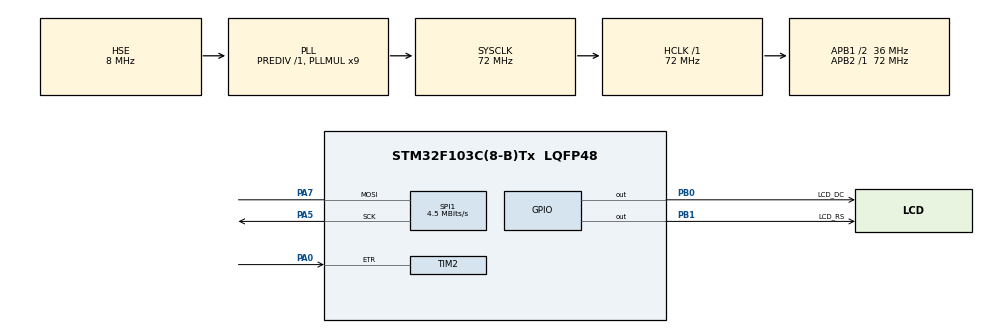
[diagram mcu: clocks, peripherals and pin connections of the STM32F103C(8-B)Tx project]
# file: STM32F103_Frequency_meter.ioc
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Mcu.Family=STM32F1
Mcu.Name=STM32F103C(8-B)Tx
Mcu.Package=LQFP48
NVIC.PriorityGroup=NVIC_PRIORITYGROUP_4
NVIC.TIM1_UP_IRQn=true\:0\:0\:false\:false\:true\:true\:true\:true
PA0-WKUP.Signal=S_TIM2_CH1_ETR
PA13.Mode=Serial_Wire
PA13.Signal=SYS_JTMS-SWDIO
PA14.Mode=Serial_Wire
PA14.Signal=SYS_JTCK-SWCLK
PA5.Mode=Simplex_Bidirectional_Master
PA5.Signal=SPI1_SCK
PA7.Mode=Simplex_Bidirectional_Master
PA7.Signal=SPI1_MOSI
PB0.GPIO_Label=LCD_DC
PB0.GPIO_Speed=GPIO_SPEED_FREQ_HIGH
PB0.Signal=GPIO_Output
PB1.GPIO_Label=LCD_RS
PB1.GPIO_Speed=GPIO_SPEED_FREQ_HIGH
PB1.Signal=GPIO_Output
PD0-OSC_IN.Mode=HSE-External-Oscillator
PD0-OSC_IN.Signal=RCC_OSC_IN
PD1-OSC_OUT.Mode=HSE-External-Oscillator
PD1-OSC_OUT.Signal=RCC_OSC_OUT
ProjectManager.HeapSize=0x200
ProjectManager.StackSize=0x400
ProjectManager.TargetToolchain=STM32CubeIDE
RCC.AHBFreq_Value=72000000
RCC.APB1CLKDivider=RCC_HCLK_DIV2
RCC.APB1Freq_Value=36000000
RCC.APB1TimFreq_Value=72000000
RCC.APB2Freq_Value=72000000
RCC.APB2TimFreq_Value=72000000
RCC.HCLKFreq_Value=72000000
RCC.PLLMUL=RCC_PLL_MUL9
RCC.PLLSourceVirtual=RCC_PLLSOURCE_HSE
RCC.RCC_MCOSource=RCC_MCO1SOURCE_HSE
RCC.SYSCLKFreq_VALUE=72000000
RCC.SYSCLKSource=RCC_SYSCLKSOURCE_PLLCLK
RCC.USBFreq_Value=72000000
SH.S_TIM2_CH1_ETR.0=TIM2_ETR,ClockSourceETR_Mode2
SPI1.BaudRatePrescaler=SPI_BAUDRATEPRESCALER_16
SPI1.CLKPolarity=SPI_POLARITY_HIGH
SPI1.CalculateBaudRate=4.5 MBits/s
SPI1.Direction=SPI_DIRECTION_1LINE
SPI1.Mode=SPI_MODE_MASTER
SPI1.VirtualType=VM_MASTER
TIM1.CounterMode=TIM_COUNTERMODE_DOWN
TIM1.Period=9999
TIM1.Prescaler=7199
TIM1.TIM_MasterOutputTrigger=TIM_TRGO_ENABLE
TIM2.TIM_MasterOutputTrigger=TIM_TRGO_UPDATE
VP_TIM1_VS_ClockSourceINT.Mode=Internal
VP_TIM1_VS_OPM.Mode=OPM_bit
VP_TIM2_VS_ClockSourceITR.Mode=TriggerSource_ITR0
VP_TIM2_VS_ControllerModeGated.Mode=Gated Mode
VP_TIM3_VS_ClockSourceITR.Mode=TriggerSource_ITR1
VP_TIM3_VS_ControllerModeClock.Mode=Clock Mode
board=custom

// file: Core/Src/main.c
/* USER CODE BEGIN Header */
/**
 ******************************************************************************
 * @file           : main.c
 * @brief          : Main program body
 ******************************************************************************
 * @attention
 *
 * Copyright (c) 2022 STMicroelectronics.
 * All rights reserved.
 *
 * This software is licensed under terms that can be found in the LICENSE file
 * in the root directory of this software component.
 * If no LICENSE file comes with this software, it is provided AS-IS.
 *
 ******************************************************************************
 */
/* USER CODE END Header */
#include "main.h"
#include "spi.h"
#include "tim.h"
#include "gpio.h"

/* USER CODE BEGIN Includes */
#include "lcd.h"
/* USER CODE END Includes */

/* USER CODE BEGIN PV */
volatile uint32_t freq = 0;
/* USER CODE END PV */

void SystemClock_Config(void);
/* USER CODE BEGIN PFP */
void HAL_TIM_PeriodElapsedCallback(TIM_HandleTypeDef *htim) {
	if (htim == &htim1) {
		freq = TIM2->CNT + (TIM3->CNT << 16);
		HAL_TIM_Base_Stop_IT(&htim1);
		__HAL_TIM_SET_COUNTER(&htim2, 0x0000);
		__HAL_TIM_SET_COUNTER(&htim3, 0x0000);
		HAL_TIM_Base_Start_IT(&htim1);
	}
}
/* USER CODE END PFP */

int main(void) {

	/* MCU Configuration--------------------------------------------------------*/

	/* Reset of all peripherals, Initializes the Flash interface and the Systick. */
	HAL_Init();

	/* Configure the system clock */
	SystemClock_Config();

	/* Initialize all configured peripherals */
	MX_GPIO_Init();
	MX_TIM1_Init();
	MX_TIM2_Init();
	MX_TIM3_Init();
	MX_SPI1_Init();
	/* USER CODE BEGIN 2 */
	HAL_Delay(100);
	HAL_TIM_Base_Start_IT(&htim1);
	HAL_TIM_Base_Start(&htim2);
	HAL_TIM_Base_Start(&htim3);

	/* USER CODE END 2 */

	/* Infinite loop */
	/* USER CODE BEGIN WHILE */

	LCD_Init(&hspi1);

	while (1) {
		/* USER CODE END WHILE */

		LCD_SetCursor(9, 9);
		LCD_Printf("%i%i.%i%i%i MHz", freq % 100000000 / 10000000,
				freq % 10000000 / 1000000, freq % 1000000 / 100000,
				freq % 100000 / 10000, freq % 1000 / 100);

	}
}

void SystemClock_Config(void) {
	RCC_OscInitTypeDef RCC_OscInitStruct = { 0 };
	RCC_ClkInitTypeDef RCC_ClkInitStruct = { 0 };

	/** Initializes the RCC Oscillators according to the specified parameters
	 * in the RCC_OscInitTypeDef structure.
	 */
	RCC_OscInitStruct.OscillatorType = RCC_OSCILLATORTYPE_HSE;
	RCC_OscInitStruct.HSEState = RCC_HSE_ON;
	RCC_OscInitStruct.HSEPredivValue = RCC_HSE_PREDIV_DIV1;
	RCC_OscInitStruct.HSIState = RCC_HSI_ON;
	RCC_OscInitStruct.PLL.PLLState = RCC_PLL_ON;
	RCC_OscInitStruct.PLL.PLLSource = RCC_PLLSOURCE_HSE;
	RCC_OscInitStruct.PLL.PLLMUL = RCC_PLL_MUL9;
	if (HAL_RCC_OscConfig(&RCC_OscInitStruct) != HAL_OK) {
		Error_Handler();
	}

	/** Initializes the CPU, AHB and APB buses clocks
	 */
	RCC_ClkInitStruct.ClockType = RCC_CLOCKTYPE_HCLK | RCC_CLOCKTYPE_SYSCLK
			| RCC_CLOCKTYPE_PCLK1 | RCC_CLOCKTYPE_PCLK2;
	RCC_ClkInitStruct.SYSCLKSource = RCC_SYSCLKSOURCE_PLLCLK;
	RCC_ClkInitStruct.AHBCLKDivider = RCC_SYSCLK_DIV1;
	RCC_ClkInitStruct.APB1CLKDivider = RCC_HCLK_DIV2;
	RCC_ClkInitStruct.APB2CLKDivider = RCC_HCLK_DIV1;

	if (HAL_RCC_ClockConfig(&RCC_ClkInitStruct, FLASH_LATENCY_2) != HAL_OK) {
		Error_Handler();
	}
}

void Error_Handler(void) {
	__disable_irq();
	while (1) {
	}
}
